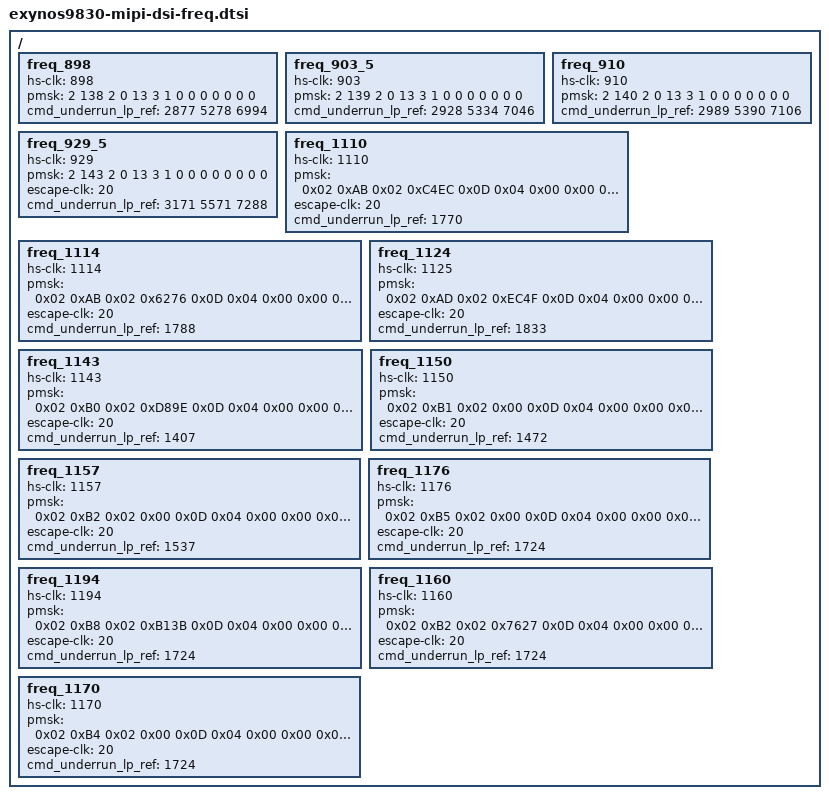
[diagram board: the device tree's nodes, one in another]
/*
 * SAMSUNG LCD Panel Device Tree Source
 *
 * Copyright (c) 2017 Samsung Electronics Co., Ltd.
 *		http://www.samsung.com
 *
 * This program is free software; you can redistribute it and/or modify
 * it under the terms of the GNU General Public License version 2 as
 * published by the Free Software Foundation.
 */

/ {
	fragment@mipi_freq {
		target-path = "/";
		__overlay__ {
			freq_898: freq_898 {
				hs-clk = <898>;
				pmsk = <
					2 138 2 0
					13 3 1 0
					0 0 0 0
					0 0 >;
				cmd_underrun_lp_ref = <2877 5278 6994>;
			};

			freq_903_5: freq_903_5 {
				hs-clk = <903>;
				pmsk = <
					2 139 2 0
					13 3 1 0
					0 0 0 0
					0 0 >;
				cmd_underrun_lp_ref = <2928 5334 7046>;
			};

			freq_910: freq_910 {
				hs-clk = <910>;
				pmsk = <
					2 140 2 0
					13 3 1 0
					0 0 0 0
					0 0 >;
				cmd_underrun_lp_ref = <2989 5390 7106>;
			};

			freq_929_5: freq_929_5 {
				hs-clk = <929>;
				pmsk = <
					2 143 2 0
					13 3 1 0
					0 0 0 0 0
					0 0 >;
				escape-clk = <20>;
				cmd_underrun_lp_ref = <3171 5571 7288>;
			};

			freq_1110: freq_1110 {
				hs-clk = <1110>;
				pmsk = <0x02 0xAB 0x02 0xC4EC
					0x0D 0x04 0x00 0x00
					0x00 0x00 0x00 0x00
					0x00 0x00>;
				escape-clk = <20>;
				cmd_underrun_lp_ref = <1770>;
			};

			freq_1114: freq_1114 {
				hs-clk = <1114>;
				pmsk = <0x02 0xAB 0x02 0x6276
					0x0D 0x04 0x00 0x00
					0x00 0x00 0x00 0x00
					0x00 0x00>;
				escape-clk = <20>;
				cmd_underrun_lp_ref = <1788>;
			};

			freq_1124: freq_1124 {
				hs-clk = <1125>;
				pmsk = <0x02 0xAD 0x02 0xEC4F
					0x0D 0x04 0x00 0x00
					0x00 0x00 0x00 0x00
					0x00 0x00>;
				escape-clk = <20>;
				cmd_underrun_lp_ref = <1833>;
			};

			freq_1143: freq_1143 {
				hs-clk = <1143>;
				pmsk = <
					0x02 0xB0 0x02 0xD89E
					0x0D 0x04 0x00 0x00
					0x00 0x00 0x00 0x00
					0x00 0x00>;
				escape-clk = <20>;
				cmd_underrun_lp_ref = <1407>;
			};
			/* 1150.5 */
			freq_1150: freq_1150 {
				hs-clk = <1150>;
				pmsk = <
					0x02 0xB1 0x02 0x00
					0x0D 0x04 0x00 0x00
					0x00 0x00 0x00 0x00
					0x00 0x00>;
				escape-clk = <20>;
				cmd_underrun_lp_ref = <1472>;
			};

			freq_1157: freq_1157 {
				hs-clk = <1157>;
				pmsk = <
					0x02 0xB2 0x02 0x00
					0x0D 0x04 0x00 0x00
					0x00 0x00 0x00 0x00
					0x00 0x00>;
				escape-clk = <20>;
				cmd_underrun_lp_ref = <1537>;
			};

			freq_1176: freq_1176 {
				hs-clk = <1176>;
				pmsk = <
					0x02 0xB5 0x02 0x00
					0x0D 0x04 0x00 0x00
					0x00 0x00 0x00 0x00
					0x00 0x00>;
				escape-clk = <20>;
				cmd_underrun_lp_ref = <1724>;
			};

			freq_1194: freq_1194 {
				hs-clk = <1194>;
				pmsk = <
					0x02 0xB8 0x02 0xB13B
					0x0D 0x04 0x00 0x00
					0x00 0x00 0x00 0x00
					0x00 0x00>;
				escape-clk = <20>;
				cmd_underrun_lp_ref = <1724>;
			};

			freq_1160: freq_1160 {
				hs-clk = <1160>;
				pmsk = <
					0x02 0xB2 0x02 0x7627
					0x0D 0x04 0x00 0x00
					0x00 0x00 0x00 0x00
					0x00 0x00>;
				escape-clk = <20>;
				cmd_underrun_lp_ref = <1724>;
			};

			freq_1170: freq_1170 {
				hs-clk = <1170>;
				pmsk = <
					0x02 0xB4 0x02 0x00
					0x0D 0x04 0x00 0x00
					0x00 0x00 0x00 0x00
					0x00 0x00>;
				escape-clk = <20>;
				cmd_underrun_lp_ref = <1724>;
			};
		};
	};
};
